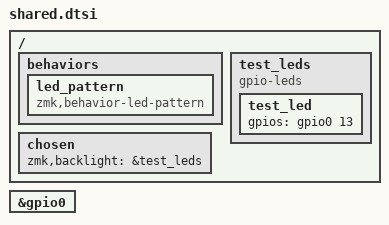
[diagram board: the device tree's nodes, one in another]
/*
 * Copyright (c) 2026 amgskobo
 * SPDX-License-Identifier: MIT
 *
 * What both halves share: the behaviors, and one GPIO LED standing in for the
 * PWM LED of real hardware - the mirror is about state, not duty cycles.
 */

/ {
    behaviors {
        led_pattern: led_pattern {
            compatible = "zmk,behavior-led-pattern";
            #binding-cells = <1>;
        };
    };

    chosen {
        zmk,backlight = &test_leds;
    };

    test_leds: test_leds {
        compatible = "gpio-leds";

        test_led: test_led {
            gpios = <&gpio0 13 GPIO_ACTIVE_HIGH>;
        };
    };
};

&gpio0 {
    status = "okay";
};
